VERSION "dbc-export 1 2026.26.6.5"

NS_ :

BS_:

BU_: DAS DIF VCLEFT

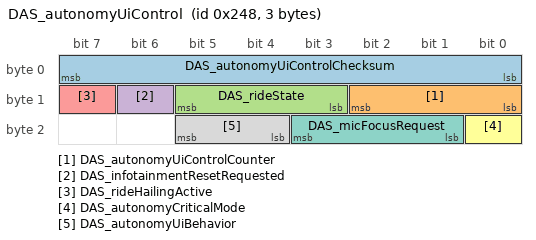
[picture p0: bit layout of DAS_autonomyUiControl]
BO_ 584 DAS_autonomyUiControl: 3 DAS
 SG_ DAS_autonomyUiControlChecksum : 0|8@1+ (1,0) [0|255] "" Vector__XXX
 SG_ DAS_autonomyUiControlCounter : 8|3@1+ (1,0) [0|7] "" Vector__XXX
 SG_ DAS_rideState : 11|3@1+ (1,0) [1|7] "" Vector__XXX
 SG_ DAS_infotainmentResetRequested : 14|1@1+ (1,0) [0|1] "" Vector__XXX
 SG_ DAS_rideHailingActive : 15|1@1+ (1,0) [0|1] "" Vector__XXX
 SG_ DAS_autonomyCriticalMode : 16|1@1+ (1,0) [0|1] "" Vector__XXX
 SG_ DAS_micFocusRequest : 17|3@1+ (1,0) [0|7] "" Vector__XXX
 SG_ DAS_autonomyUiBehavior : 20|2@1+ (1,0) [1|3] "" Vector__XXX

BO_ 1622 DIF_info: 8 DIF
 SG_ DIF_infoIndex M : 0|8@1+ (1,0) [0|255] "" Vector__XXX
 SG_ DIF_buildType m10 : 8|3@1+ (1,0) [0|7] "" Vector__XXX
 SG_ DIF_buildConfigurationId m10 : 16|16@1+ (1,0) [0|65535] "" Vector__XXX
 SG_ DIF_hardwareId m10 : 32|8@1+ (1,0) [0|252] "" Vector__XXX
 SG_ DIF_componentId m10 : 48|16@1+ (1,0) [0|65535] "" Vector__XXX
 SG_ DIF_pcbaId m11 : 16|8@1+ (1,0) [0|255] "" Vector__XXX
 SG_ DIF_assemblyId m11 : 24|8@1+ (1,0) [0|255] "" Vector__XXX
 SG_ DIF_usageId m11 : 32|16@1+ (1,0) [0|65535] "" Vector__XXX
 SG_ DIF_subUsageId m11 : 48|16@1+ (1,0) [0|65535] "" Vector__XXX
 SG_ DIF_motorType m12 : 8|6@1+ (1,0) [1|63] "" Vector__XXX
 SG_ DIF_siliconType m12 : 16|1@1+ (1,0) [0|1] "" Vector__XXX
 SG_ DIF_mechSafeStateType m12 : 24|2@1+ (1,0) [1|3] "" Vector__XXX
 SG_ DIF_applicationCrc m13 : 32|32@1+ (1,0) [0|4294967295] "" Vector__XXX
 SG_ DIF_oilPumpBuildType m16 : 8|3@1+ (1,0) [0|7] "" Vector__XXX
 SG_ DIF_oilPumpAppCrc m16 : 16|32@1+ (1,0) [0|4294967295] "" Vector__XXX
 SG_ DIF_FPGA_version m16 : 48|8@1+ (1,0) [0|254] "" Vector__XXX
 SG_ DIF_appGitHash m17 : 8|56@1+ (1,0) [0|7.20575940379e+16] "" Vector__XXX
 SG_ DIF_bootGitHash m18 : 8|56@1+ (1,0) [0|7.20575940379e+16] "" Vector__XXX
 SG_ DIF_platformTyp m19 : 8|8@1+ (1,0) [0|255] "" Vector__XXX
 SG_ DIF_infoBootLdUdsProtocolVersion m20 : 8|8@1+ (1,0) [0|255] "" Vector__XXX
 SG_ DIF_bootloaderCrc m20 : 32|32@1+ (1,0) [0|4294967295] "" Vector__XXX
 SG_ DIF_oilPumpPcbaId m33 : 8|8@1+ (1,0) [0|255] "" Vector__XXX
 SG_ DIF_oilPumpAssemblyId m33 : 16|8@1+ (1,0) [0|255] "" Vector__XXX
 SG_ DIF_oilPumpUsageId m33 : 24|16@1+ (1,0) [0|65535] "" Vector__XXX
 SG_ DIF_refRotorFlux m35 : 8|16@1+ (0.0001,0) [0|6.5535] "Wb" Vector__XXX
 SG_ DIF_refRotorOffset m35 : 24|12@1- (0.1,0) [-180|180] "deg" Vector__XXX
 SG_ DIF_speedWearTotal m36 : 8|8@1+ (0.4,0) [0|100] "%" Vector__XXX
 SG_ DIF_torqueWearTotal m36 : 24|8@1+ (0.02,0) [0|5.08] "1" Vector__XXX

BO_ 258 VCLEFT_doorStatus: 8 VCLEFT
 SG_ VCLEFT_doorClosureStatusFront : 0|4@1+ (1,0) [1|15] "" Vector__XXX
 SG_ VCLEFT_doorClosureStatusRear : 4|4@1+ (1,0) [1|15] "" Vector__XXX
 SG_ VCLEFT_frontLatchSwitch : 8|1@1+ (1,0) [0|1] "" Vector__XXX
 SG_ VCLEFT_rearLatchSwitch : 9|1@1+ (1,0) [0|1] "" Vector__XXX
 SG_ VCLEFT_frontHandlePulled : 10|1@1+ (1,0) [0|1] "" Vector__XXX
 SG_ VCLEFT_rearHandlePulled : 11|1@1+ (1,0) [0|1] "" Vector__XXX
 SG_ VCLEFT_frontRelActuatorSwitch : 12|1@1+ (1,0) [0|1] "" Vector__XXX
 SG_ VCLEFT_rearRelActuatorSwitch : 13|1@1+ (1,0) [0|1] "" Vector__XXX
 SG_ VCLEFT_frontLatchStatus : 14|4@1+ (1,0) [1|15] "" Vector__XXX
 SG_ VCLEFT_rearLatchStatus : 18|4@1+ (1,0) [1|15] "" Vector__XXX
 SG_ VCLEFT_lastDoorReqSourceFront : 22|3@1+ (1,0) [0|7] "" Vector__XXX
 SG_ VCLEFT_lastDoorReqSourceRear : 25|3@1+ (1,0) [0|7] "" Vector__XXX
 SG_ VCLEFT_frontIntSwitchFaulted : 28|1@1+ (1,0) [0|1] "" Vector__XXX
 SG_ VCLEFT_rearIntSwitchFaulted : 29|1@1+ (1,0) [0|1] "" Vector__XXX
 SG_ VCLEFT_frontIntSwitchPressed : 31|1@1+ (1,0) [0|1] "" Vector__XXX
 SG_ VCLEFT_rearIntSwitchPressed : 32|1@1+ (1,0) [0|1] "" Vector__XXX
 SG_ VCLEFT_mirrorTiltXPosition : 33|8@1+ (0.02,0) [0|5] "V" Vector__XXX
 SG_ VCLEFT_mirrorTiltYPosition : 41|8@1+ (0.02,0) [0|5] "V" Vector__XXX
 SG_ VCLEFT_mirrorState : 49|3@1+ (1,0) [0|7] "" Vector__XXX
 SG_ VCLEFT_mirrorFoldState : 52|3@1+ (1,0) [0|7] "" Vector__XXX
 SG_ VCLEFT_mirrorRecallState : 55|3@1+ (1,0) [0|7] "" Vector__XXX
 SG_ VCLEFT_mirrorHeatState : 58|3@1+ (1,0) [1|7] "" Vector__XXX
 SG_ VCLEFT_rearHandlePulledPersist : 61|1@1+ (1,0) [0|1] "" Vector__XXX
 SG_ VCLEFT_frontHandlePulledPersist : 62|1@1+ (1,0) [0|1] "" Vector__XXX
 SG_ VCLEFT_mirrorDipped : 63|1@1+ (1,0) [0|1] "" Vector__XXX

BO_TX_BU_ 584 : DAS;
BO_TX_BU_ 1622 : DIF;
BO_TX_BU_ 258 : VCLEFT;

CM_ "Tesla Bayberry CAN bus database; bus bus1 (inferred PARTY); firmware 2026.26.6.5. Decoded CAN signal definitions (layout, scaling, units, value tables).";
CM_ BU_ DAS "Driver assistance computer";
CM_ BU_ DIF "Front drive inverter";
CM_ BU_ VCLEFT "Left body controller";
CM_ BO_ 584 "Driver assistance computer message: autonomy ui control; frame length from the layout, not yet observed on a vehicle bus";
CM_ SG_ 584 DAS_autonomyUiControlChecksum "Driver assistance computer: autonomy ui control checksum";
CM_ SG_ 584 DAS_autonomyUiControlCounter "Driver assistance computer: autonomy ui control counter";
CM_ SG_ 584 DAS_rideState "Driver assistance computer: ride state; raw 0 = signal not available (SNA)";
CM_ SG_ 584 DAS_infotainmentResetRequested "Driver assistance computer: infotainment reset requested";
CM_ SG_ 584 DAS_rideHailingActive "Driver assistance computer: ride hailing active";
CM_ SG_ 584 DAS_autonomyCriticalMode "Driver assistance computer: autonomy critical mode";
CM_ SG_ 584 DAS_micFocusRequest "Driver assistance computer: mic focus request";
CM_ SG_ 584 DAS_autonomyUiBehavior "Driver assistance computer: autonomy ui behavior; raw 0 = signal not available (SNA)";
CM_ BO_ 1622 "Front drive inverter message: info; frame length from the layout, not yet observed on a vehicle bus";
CM_ SG_ 1622 DIF_infoIndex "Front drive inverter: info index";
CM_ SG_ 1622 DIF_buildType "Front drive inverter: build type";
CM_ SG_ 1622 DIF_buildConfigurationId "Front drive inverter: build configuration id";
CM_ SG_ 1622 DIF_hardwareId "Front drive inverter: hardware id";
CM_ SG_ 1622 DIF_componentId "Front drive inverter: component id";
CM_ SG_ 1622 DIF_pcbaId "Front drive inverter: pcba id";
CM_ SG_ 1622 DIF_assemblyId "Front drive inverter: assembly id";
CM_ SG_ 1622 DIF_usageId "Front drive inverter: usage id";
CM_ SG_ 1622 DIF_subUsageId "Front drive inverter: sub usage id";
CM_ SG_ 1622 DIF_motorType "Front drive inverter: motor type; raw 0 = signal not available (SNA)";
CM_ SG_ 1622 DIF_siliconType "Front drive inverter: silicon type";
CM_ SG_ 1622 DIF_mechSafeStateType "Front drive inverter: mech safe state type; raw 0 = signal not available (SNA)";
CM_ SG_ 1622 DIF_applicationCrc "Front drive inverter: application crc";
CM_ SG_ 1622 DIF_oilPumpBuildType "Front drive inverter: oil pump build type";
CM_ SG_ 1622 DIF_oilPumpAppCrc "Front drive inverter: oil pump app crc";
CM_ SG_ 1622 DIF_FPGA_version "Front drive inverter: FPGA version; raw 255 = signal not available (SNA)";
CM_ SG_ 1622 DIF_appGitHash "Front drive inverter: app git hash";
CM_ SG_ 1622 DIF_bootGitHash "Front drive inverter: boot git hash";
CM_ SG_ 1622 DIF_platformTyp "Front drive inverter: platform typ";
CM_ SG_ 1622 DIF_infoBootLdUdsProtocolVersion "Front drive inverter: info boot ld uds protocol version";
CM_ SG_ 1622 DIF_bootloaderCrc "Front drive inverter: bootloader crc";
CM_ SG_ 1622 DIF_oilPumpPcbaId "Front drive inverter: oil pump pcba id";
CM_ SG_ 1622 DIF_oilPumpAssemblyId "Front drive inverter: oil pump assembly id";
CM_ SG_ 1622 DIF_oilPumpUsageId "Front drive inverter: oil pump usage id";
CM_ SG_ 1622 DIF_refRotorFlux "Front drive inverter: ref rotor flux";
CM_ SG_ 1622 DIF_refRotorOffset "Front drive inverter: ref rotor offset; raw 2048 = signal not available (SNA)";
CM_ SG_ 1622 DIF_speedWearTotal "Front drive inverter: speed wear total; raw 255 = signal not available (SNA)";
CM_ SG_ 1622 DIF_torqueWearTotal "Front drive inverter: torque wear total; raw 255 = signal not available (SNA)";
CM_ BO_ 258 "Left body controller message: door status; frame length from the layout, not yet observed on a vehicle bus";
CM_ SG_ 258 VCLEFT_doorClosureStatusFront "Status of the door from a closures perspective; raw 0 = signal not available (SNA)";
CM_ SG_ 258 VCLEFT_doorClosureStatusRear "Status of the door from a closures perspective; raw 0 = signal not available (SNA)";
CM_ SG_ 258 VCLEFT_frontLatchSwitch "State of front left door latch switch representing door open/closed. 0 is open and 1 is closed";
CM_ SG_ 258 VCLEFT_rearLatchSwitch "State of rear left door latch switch representing door open/closed. 0 is open and 1 is closed";
CM_ SG_ 258 VCLEFT_frontHandlePulled "Left body controller: front handle pulled";
CM_ SG_ 258 VCLEFT_rearHandlePulled "Left body controller: rear handle pulled";
CM_ SG_ 258 VCLEFT_frontRelActuatorSwitch "State of front left door latch switch representing latch arm/unarmed. Disarms while door handle is pulled.";
CM_ SG_ 258 VCLEFT_rearRelActuatorSwitch "State of rear left door latch switch representing latch arm/unarmed. Disarms while door handle is pulled";
CM_ SG_ 258 VCLEFT_frontLatchStatus "Status of left front door latch; raw 0 = signal not available (SNA)";
CM_ SG_ 258 VCLEFT_rearLatchStatus "Status of rear left door latch; raw 0 = signal not available (SNA)";
CM_ SG_ 258 VCLEFT_lastDoorReqSourceFront "last source of front door open request";
CM_ SG_ 258 VCLEFT_lastDoorReqSourceRear "last source of rear door open request";
CM_ SG_ 258 VCLEFT_frontIntSwitchFaulted "Indicates if the front door interior button is faulted";
CM_ SG_ 258 VCLEFT_rearIntSwitchFaulted "Indicates if the rear door interior button is faulted";
CM_ SG_ 258 VCLEFT_frontIntSwitchPressed "Left body controller: front int switch pressed";
CM_ SG_ 258 VCLEFT_rearIntSwitchPressed "Left body controller: rear int switch pressed";
CM_ SG_ 258 VCLEFT_mirrorTiltXPosition "Value representing left side view mirror tilt horizontal position";
CM_ SG_ 258 VCLEFT_mirrorTiltYPosition "Value representing left side view mirror tilt vertical position";
CM_ SG_ 258 VCLEFT_mirrorState "State of the left side view mirror.";
CM_ SG_ 258 VCLEFT_mirrorFoldState "Fold state for the left side view mirror";
CM_ SG_ 258 VCLEFT_mirrorRecallState "State of Mirror Recall.";
CM_ SG_ 258 VCLEFT_mirrorHeatState "Left body controller: mirror heat state; raw 0 = signal not available (SNA)";
CM_ SG_ 258 VCLEFT_rearHandlePulledPersist "Left body controller: rear handle pulled persist";
CM_ SG_ 258 VCLEFT_frontHandlePulledPersist "Left body controller: front handle pulled persist";
CM_ SG_ 258 VCLEFT_mirrorDipped "Reports if the side view mirrors in are in the dipped position.";
BA_DEF_ "BusType" STRING;
BA_DEF_ "DBName" STRING;
BA_DEF_ "Baudrate" INT 0 1000000;
BA_DEF_ "BaudrateCANFD" INT 0 16000000;
BA_DEF_ "Manufacturer" STRING;
BA_DEF_ "FirmwareVersion" STRING;
BA_DEF_ "VehicleModel" STRING;
BA_DEF_ BU_ "ECU" STRING;
BA_DEF_ BO_ "GenMsgCycleTime" INT 0 3600000;
BA_DEF_ BO_ "GenMsgSendType" ENUM "Cyclic","NotUsed","NotUsed","NotUsed","NotUsed","NotUsed","NotUsed","IfActive","NoMsgSendType","NotUsed";
BA_DEF_ BO_ "VFrameFormat" ENUM "StandardCAN","ExtendedCAN","reserved","J1939PG","reserved","reserved","reserved","reserved","reserved","reserved","reserved","reserved","reserved","reserved","StandardCAN_FD","ExtendedCAN_FD";
BA_DEF_ BO_ "CANFD_BRS" ENUM "0","1";
BA_DEF_ SG_ "GenSigSNA" STRING;
BA_DEF_ SG_ "Confidence" ENUM "validated","plausible","layout-only","contradicted";
BA_DEF_DEF_ "BusType" "CAN";
BA_DEF_DEF_ "DBName" "";
BA_DEF_DEF_ "Baudrate" 500000;
BA_DEF_DEF_ "BaudrateCANFD" 2000000;
BA_DEF_DEF_ "Manufacturer" "";
BA_DEF_DEF_ "FirmwareVersion" "";
BA_DEF_DEF_ "VehicleModel" "";
BA_DEF_DEF_ "ECU" "";
BA_DEF_DEF_ "GenMsgCycleTime" 0;
BA_DEF_DEF_ "GenMsgSendType" "NoMsgSendType";
BA_DEF_DEF_ "VFrameFormat" "StandardCAN";
BA_DEF_DEF_ "CANFD_BRS" "1";
BA_DEF_DEF_ "GenSigSNA" "";
BA_DEF_DEF_ "Confidence" "layout-only";
BA_ "DBName" "Bayberry_PARTY";
BA_ "Manufacturer" "Tesla";
BA_ "FirmwareVersion" "2026.26.6.5";
BA_ "VehicleModel" "Bayberry";
BA_ "ECU" BU_ DAS "DAS";
BA_ "ECU" BU_ DIF "DIF";
BA_ "ECU" BU_ VCLEFT "VCLEFT";
BA_ "GenMsgCycleTime" BO_ 584 100;
BA_ "GenMsgSendType" BO_ 584 0;
BA_ "GenMsgCycleTime" BO_ 1622 1000;
BA_ "GenMsgSendType" BO_ 1622 0;
BA_ "GenMsgCycleTime" BO_ 258 100;
BA_ "GenMsgSendType" BO_ 258 0;
BA_ "Confidence" SG_ 584 DAS_autonomyUiControlChecksum 0;
BA_ "Confidence" SG_ 584 DAS_autonomyUiControlCounter 0;
BA_ "Confidence" SG_ 584 DAS_rideState 0;
BA_ "GenSigSNA" SG_ 584 DAS_rideState "0";
BA_ "Confidence" SG_ 584 DAS_infotainmentResetRequested 0;
BA_ "Confidence" SG_ 584 DAS_rideHailingActive 0;
BA_ "Confidence" SG_ 584 DAS_autonomyCriticalMode 0;
BA_ "Confidence" SG_ 584 DAS_micFocusRequest 0;
BA_ "Confidence" SG_ 584 DAS_autonomyUiBehavior 0;
BA_ "GenSigSNA" SG_ 584 DAS_autonomyUiBehavior "0";
BA_ "Confidence" SG_ 1622 DIF_infoIndex 1;
BA_ "Confidence" SG_ 1622 DIF_buildType 0;
BA_ "Confidence" SG_ 1622 DIF_buildConfigurationId 0;
BA_ "Confidence" SG_ 1622 DIF_hardwareId 0;
BA_ "Confidence" SG_ 1622 DIF_componentId 0;
BA_ "Confidence" SG_ 1622 DIF_pcbaId 0;
BA_ "Confidence" SG_ 1622 DIF_assemblyId 0;
BA_ "Confidence" SG_ 1622 DIF_usageId 0;
BA_ "Confidence" SG_ 1622 DIF_subUsageId 0;
BA_ "Confidence" SG_ 1622 DIF_motorType 0;
BA_ "GenSigSNA" SG_ 1622 DIF_motorType "0";
BA_ "Confidence" SG_ 1622 DIF_siliconType 0;
BA_ "Confidence" SG_ 1622 DIF_mechSafeStateType 0;
BA_ "GenSigSNA" SG_ 1622 DIF_mechSafeStateType "0";
BA_ "Confidence" SG_ 1622 DIF_applicationCrc 0;
BA_ "Confidence" SG_ 1622 DIF_oilPumpBuildType 0;
BA_ "Confidence" SG_ 1622 DIF_oilPumpAppCrc 0;
BA_ "Confidence" SG_ 1622 DIF_FPGA_version 0;
BA_ "GenSigSNA" SG_ 1622 DIF_FPGA_version "255";
BA_ "Confidence" SG_ 1622 DIF_appGitHash 0;
BA_ "Confidence" SG_ 1622 DIF_bootGitHash 0;
BA_ "Confidence" SG_ 1622 DIF_platformTyp 0;
BA_ "Confidence" SG_ 1622 DIF_infoBootLdUdsProtocolVersion 0;
BA_ "Confidence" SG_ 1622 DIF_bootloaderCrc 0;
BA_ "Confidence" SG_ 1622 DIF_oilPumpPcbaId 0;
BA_ "Confidence" SG_ 1622 DIF_oilPumpAssemblyId 0;
BA_ "Confidence" SG_ 1622 DIF_oilPumpUsageId 0;
BA_ "Confidence" SG_ 1622 DIF_refRotorFlux 0;
BA_ "Confidence" SG_ 1622 DIF_refRotorOffset 0;
BA_ "GenSigSNA" SG_ 1622 DIF_refRotorOffset "2048";
BA_ "Confidence" SG_ 1622 DIF_speedWearTotal 0;
BA_ "GenSigSNA" SG_ 1622 DIF_speedWearTotal "255";
BA_ "Confidence" SG_ 1622 DIF_torqueWearTotal 0;
BA_ "GenSigSNA" SG_ 1622 DIF_torqueWearTotal "255";
BA_ "Confidence" SG_ 258 VCLEFT_doorClosureStatusFront 0;
BA_ "GenSigSNA" SG_ 258 VCLEFT_doorClosureStatusFront "0";
BA_ "Confidence" SG_ 258 VCLEFT_doorClosureStatusRear 0;
BA_ "GenSigSNA" SG_ 258 VCLEFT_doorClosureStatusRear "0";
BA_ "Confidence" SG_ 258 VCLEFT_frontLatchSwitch 0;
BA_ "Confidence" SG_ 258 VCLEFT_rearLatchSwitch 0;
BA_ "Confidence" SG_ 258 VCLEFT_frontHandlePulled 0;
BA_ "Confidence" SG_ 258 VCLEFT_rearHandlePulled 0;
BA_ "Confidence" SG_ 258 VCLEFT_frontRelActuatorSwitch 0;
BA_ "Confidence" SG_ 258 VCLEFT_rearRelActuatorSwitch 0;
BA_ "Confidence" SG_ 258 VCLEFT_frontLatchStatus 0;
BA_ "GenSigSNA" SG_ 258 VCLEFT_frontLatchStatus "0";
BA_ "Confidence" SG_ 258 VCLEFT_rearLatchStatus 0;
BA_ "GenSigSNA" SG_ 258 VCLEFT_rearLatchStatus "0";
BA_ "Confidence" SG_ 258 VCLEFT_lastDoorReqSourceFront 0;
BA_ "Confidence" SG_ 258 VCLEFT_lastDoorReqSourceRear 0;
BA_ "Confidence" SG_ 258 VCLEFT_frontIntSwitchFaulted 0;
BA_ "Confidence" SG_ 258 VCLEFT_rearIntSwitchFaulted 0;
BA_ "Confidence" SG_ 258 VCLEFT_frontIntSwitchPressed 0;
BA_ "Confidence" SG_ 258 VCLEFT_rearIntSwitchPressed 0;
BA_ "Confidence" SG_ 258 VCLEFT_mirrorTiltXPosition 0;
BA_ "Confidence" SG_ 258 VCLEFT_mirrorTiltYPosition 0;
BA_ "Confidence" SG_ 258 VCLEFT_mirrorState 0;
BA_ "Confidence" SG_ 258 VCLEFT_mirrorFoldState 0;
BA_ "Confidence" SG_ 258 VCLEFT_mirrorRecallState 0;
BA_ "Confidence" SG_ 258 VCLEFT_mirrorHeatState 0;
BA_ "GenSigSNA" SG_ 258 VCLEFT_mirrorHeatState "0";
BA_ "Confidence" SG_ 258 VCLEFT_rearHandlePulledPersist 0;
BA_ "Confidence" SG_ 258 VCLEFT_frontHandlePulledPersist 0;
BA_ "Confidence" SG_ 258 VCLEFT_mirrorDipped 0;
VAL_ 584 DAS_rideState 6 "PULLOVER" 5 "IDLE" 4 "ENROUTE" 3 "WAITING" 2 "SUMMON" 1 "INACTIVE" 0 "SNA" ;
VAL_ 584 DAS_micFocusRequest 4 "ENTIRE_CABIN" 3 "FRONT_ROW" 2 "FRONT_PASSENGER" 1 "FRONT_DRIVER" 0 "NONE" ;
VAL_ 584 DAS_autonomyUiBehavior 3 "AUTONOMY_SUMMON" 2 "RIDEHAILING_ROAMING" 1 "NONE" 0 "SNA" ;
VAL_ 1622 DIF_infoIndex 255 "INFO_END" 44 "TRACKING_DATA_5" 43 "TRACKING_DATA_4" 42 "TRACKING_DATA_3" 41 "TRACKING_DATA_2" 40 "TRACKING_DATA_1" 34 "INFO_SUBCOMPONENT2_HWID" 33 "INFO_SUBCOMPONENT_HWID" 32 "INFO_SUBCOMPONENT2_GITHASH" 31 "INFO_SUBCOMPONENT_GITHASH" 23 "INFO_SUBCOMPONENT2" 20 "INFO_UDS_PROTOCOL_BOOTCRC" 19 "INFO_VERSION_DEPRECATED" 18 "INFO_BOOTLOADER_GITHASH" 17 "INFO_APP_GITHASH" 16 "INFO_SUBCOMPONENT" 15 "INFO_BOOTLOADER_CRC" 14 "INFO_BOOTLOADER_SVN" 13 "INFO_APP_CRC" 11 "INFO_PCBAID_ASSYID_USAGEID" 10 "INFO_BUILD_HWID_COMPONENTID" 9 "INFO_DEPRECATED_9" 8 "INFO_DEPRECATED_8" 7 "INFO_DEPRECATED_7" 6 "INFO_DEPRECATED_6" 5 "INFO_DEPRECATED_5" 4 "INFO_DEPRECATED_4" 3 "INFO_DEPRECATED_3" 2 "INFO_DEPRECATED_2" 1 "INFO_DEPRECATED_1" 0 "INFO_DEPRECATED_0" ;
VAL_ 1622 DIF_buildType 4 "INFO_MFG_BUILD" 3 "INFO_TRACEABLE_CI_BUILD" 2 "INFO_LOCAL_BUILD" 1 "INFO_PLATFORM_BUILD" 0 "INFO_UNKNOWN_BUILD" ;
VAL_ 1622 DIF_hardwareId 252 "CONFIGURABLE_HWID_PLACEHOLDER" ;
VAL_ 1622 DIF_motorType 36 "DI_MOTOR_PM240C" 35 "DI_MOTOR_IM188A" 34 "DI_MOTOR_IM130E_AL" 32 "DI_MOTOR_PM261D" 31 "DI_MOTOR_PM216E" 20 "DI_MOTOR_PM215D_1KV" 18 "DI_MOTOR_IM260E_1KV" 17 "DI_MOTOR_IM260D_1KV" 16 "DI_MOTOR_PM261C" 15 "DI_MOTOR_PM215C_1KV" 14 "DI_MOTOR_IM260C_1KV" 13 "DI_MOTOR_PM215A_1KV" 12 "DI_MOTOR_IM260A_1KV" 11 "DI_MOTOR_IM228HEA" 10 "DI_MOTOR_PM228HEA" 9 "DI_MOTOR_PM275C" 8 "DI_MOTOR_PM291D" 7 "DI_MOTOR_PM291C" 6 "DI_MOTOR_PM228C" 5 "DI_MOTOR_PM350B" 4 "DI_MOTOR_PM275B" 3 "DI_MOTOR_IM130D_AL" 2 "DI_MOTOR_IM130D" 1 "DI_MOTOR_PM216D" 0 "DI_MOTOR_SNA" ;
VAL_ 1622 DIF_siliconType 1 "IGBT" 0 "MOSFET" ;
VAL_ 1622 DIF_mechSafeStateType 2 "DI_MECH_SAFE_STATE_TYPE_PRESENT" 1 "DI_MECH_SAFE_STATE_TYPE_NONE" 0 "DI_MECH_SAFE_STATE_TYPE_SNA" ;
VAL_ 1622 DIF_oilPumpBuildType 4 "INFO_MFG_BUILD" 3 "INFO_TRACEABLE_CI_BUILD" 2 "INFO_LOCAL_BUILD" 1 "INFO_PLATFORM_BUILD" 0 "INFO_UNKNOWN_BUILD" ;
VAL_ 1622 DIF_FPGA_version 255 "SNA" 254 "LOCAL_BUILD" ;
VAL_ 1622 DIF_refRotorOffset -2048 "SNA" ;
VAL_ 1622 DIF_speedWearTotal 255 "SNA" ;
VAL_ 1622 DIF_torqueWearTotal 255 "SNA" ;
VAL_ 258 VCLEFT_doorClosureStatusFront 8 "CLOSURE_STATUS_FAULT" 2 "CLOSURE_STATUS_CLOSED" 1 "CLOSURE_STATUS_OPEN" 0 "CLOSURE_STATUS_SNA" ;
VAL_ 258 VCLEFT_doorClosureStatusRear 8 "CLOSURE_STATUS_FAULT" 2 "CLOSURE_STATUS_CLOSED" 1 "CLOSURE_STATUS_OPEN" 0 "CLOSURE_STATUS_SNA" ;
VAL_ 258 VCLEFT_frontLatchStatus 8 "LATCH_FAULT" 7 "LATCH_DEFAULT" 6 "LATCH_TIMEOUT" 5 "LATCH_AJAR" 4 "LATCH_OPENING" 3 "LATCH_CLOSING" 2 "LATCH_CLOSED" 1 "LATCH_OPENED" 0 "LATCH_SNA" ;
VAL_ 258 VCLEFT_rearLatchStatus 8 "LATCH_FAULT" 7 "LATCH_DEFAULT" 6 "LATCH_TIMEOUT" 5 "LATCH_AJAR" 4 "LATCH_OPENING" 3 "LATCH_CLOSING" 2 "LATCH_CLOSED" 1 "LATCH_OPENED" 0 "LATCH_SNA" ;
VAL_ 258 VCLEFT_lastDoorReqSourceFront 4 "DOOR_REQUEST_SOURCE_ECU" 3 "DOOR_REQUEST_SOURCE_VCSEC" 2 "DOOR_REQUEST_SOURCE_EXTERIOR_HANDLE" 1 "DOOR_REQUEST_SOURCE_INTERIOR_BUTTON" 0 "DOOR_REQUEST_SOURCE_UNKNOWN" ;
VAL_ 258 VCLEFT_lastDoorReqSourceRear 4 "DOOR_REQUEST_SOURCE_ECU" 3 "DOOR_REQUEST_SOURCE_VCSEC" 2 "DOOR_REQUEST_SOURCE_EXTERIOR_HANDLE" 1 "DOOR_REQUEST_SOURCE_INTERIOR_BUTTON" 0 "DOOR_REQUEST_SOURCE_UNKNOWN" ;
VAL_ 258 VCLEFT_mirrorState 5 "MIRROR_STATE_CALIBRATION" 4 "MIRROR_STATE_RECALL" 3 "MIRROR_STATE_FOLD_UNFOLD" 2 "MIRROR_STATE_TILT_Y" 1 "MIRROR_STATE_TILT_X" 0 "MIRROR_STATE_IDLE" ;
VAL_ 258 VCLEFT_mirrorFoldState 4 "MIRROR_FOLD_STATE_UNFOLDING" 3 "MIRROR_FOLD_STATE_FOLDING" 2 "MIRROR_FOLD_STATE_UNFOLDED" 1 "MIRROR_FOLD_STATE_FOLDED" 0 "MIRROR_FOLD_STATE_UNKNOWN" ;
VAL_ 258 VCLEFT_mirrorRecallState 5 "MIRROR_RECALL_STATE_RECALLING_STOPPED" 4 "MIRROR_RECALL_STATE_RECALLING_FAILED" 3 "MIRROR_RECALL_STATE_RECALLING_COMPLETE" 2 "MIRROR_RECALL_STATE_RECALLING_AXIS_2" 1 "MIRROR_RECALL_STATE_RECALLING_AXIS_1" 0 "MIRROR_RECALL_STATE_INIT" ;
VAL_ 258 VCLEFT_mirrorHeatState 4 "HEATER_STATE_FAULT" 3 "HEATER_STATE_OFF_UNAVAILABLE" 2 "HEATER_STATE_OFF" 1 "HEATER_STATE_ON" 0 "HEATER_STATE_SNA" ;
